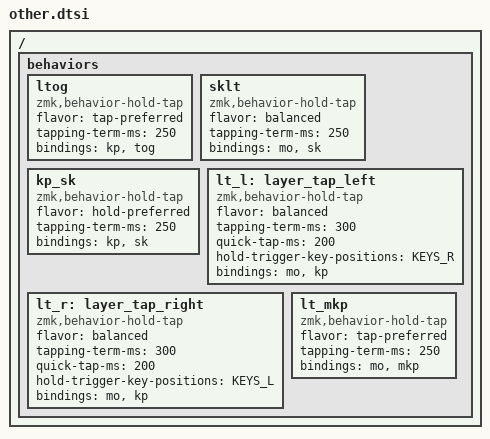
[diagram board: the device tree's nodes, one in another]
#include <dt-bindings/zmk/outputs.h>

/ {

    behaviors {

       /*
        * Layer Toggle
        *
        * Usage: &ltog LGUI NAV
        * Tap: Layer Toggle
        * Hold: Keypress
        */
        ltog: ltog {
            compatible = "zmk,behavior-hold-tap";
            #binding-cells = <2>;
            flavor = "tap-preferred";
            tapping-term-ms = <250>;
            bindings = <&kp>, <&tog>;
        };

       /*
        * Layer Sticky Key Tap Toggle
        *
        * Usage: &sklt NUM RSHFT
        * Tap: Sticky Key
        * Hold: Layer
        */
        sklt: sklt {
            compatible = "zmk,behavior-hold-tap";
            #binding-cells = <2>;
            flavor = "balanced";
            tapping-term-ms = <250>;
            bindings = <&mo>, <&sk>;
        };

       /*
        * Layer Sticky Key Tap Toggle
        *
        * Usage: &kp_sk RSHFT RSHFT
        * Tap: Sticky Key RSHIFT
        * Hold: Regular RSHIFT
        */
        kp_sk: kp_sk {
            compatible = "zmk,behavior-hold-tap";
            #binding-cells = <2>;
            flavor = "hold-preferred";
            tapping-term-ms = <250>;
            bindings = <&kp>, <&sk>;
        };

       /*
        * Timerless Layer Tap
        *
        * Works similarly timerless homerow mods. It activates the
        * layer hold immediately for keys on the right side.
        */
        lt_l: layer_tap_left {
            compatible = "zmk,behavior-hold-tap";
            #binding-cells = <2>;
            flavor = "balanced";
            tapping-term-ms = <300>;
			quick-tap-ms = <200>;

            // Activate layer function immediately if a key on the right
            // side of the keyboard is used.
            hold-trigger-key-positions = <KEYS_R>;

            bindings = <&mo>, <&kp>;
        };

        lt_r: layer_tap_right {
            compatible = "zmk,behavior-hold-tap";
            #binding-cells = <2>;
            flavor = "balanced";
            tapping-term-ms = <300>;
			quick-tap-ms = <200>;

            // Activate layer function immediately if a key on the left
            // side of the keyboard is used.
            hold-trigger-key-positions = <KEYS_L>;

            bindings = <&mo>, <&kp>;
        };

       /*
        * Layer & mouse key
        *
        * Usage: &lt_mkp NUM RCLK
        * Tap: Mouse RCLK
        * Hold: Layer NUM
        */
        lt_mkp: lt_mkp {
            compatible = "zmk,behavior-hold-tap";
            #binding-cells = <2>;
            flavor = "tap-preferred";
            tapping-term-ms = <250>;
            bindings = <&mo>, <&mkp>;
        };
    };
};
